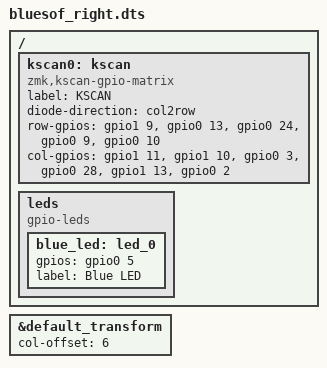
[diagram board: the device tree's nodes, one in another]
/*
 * Copyright (c) 2020 Eric Lau
 *
 * SPDX-License-Identifier: MIT
 */

#include "bluesof.dtsi"

/{
	kscan0: kscan {
		compatible = "zmk,kscan-gpio-matrix";
		label = "KSCAN";

		diode-direction = "col2row";
		row-gpios
			= <&gpio1  9 (GPIO_ACTIVE_HIGH | GPIO_PULL_DOWN)>
			, <&gpio0 13 (GPIO_ACTIVE_HIGH | GPIO_PULL_DOWN)>
			, <&gpio0 24 (GPIO_ACTIVE_HIGH | GPIO_PULL_DOWN)>
			, <&gpio0  9 (GPIO_ACTIVE_HIGH | GPIO_PULL_DOWN)>
			, <&gpio0 10 (GPIO_ACTIVE_HIGH | GPIO_PULL_DOWN)>
			;

		col-gpios
			= <&gpio1 11 GPIO_ACTIVE_HIGH>
			, <&gpio1 10 GPIO_ACTIVE_HIGH>
			, <&gpio0  3 GPIO_ACTIVE_HIGH>
			, <&gpio0 28 GPIO_ACTIVE_HIGH>
			, <&gpio1 13 GPIO_ACTIVE_HIGH>
			, <&gpio0  2 GPIO_ACTIVE_HIGH>
			;
	};

	leds {
		compatible = "gpio-leds";
		blue_led: led_0 {
			gpios = <&gpio0 5 GPIO_ACTIVE_HIGH>;
			label = "Blue LED";
		};
		};
	// vbatt {
	// 	compatible = "zmk,battery-voltage-divider";
	// 	label = "BATTERY";
	// 	io-channels = <&adc 2>;
	// 	output-ohms = <2000000>;
	// 	full-ohms = <(2000000 + 820000)>;
	// };

};

&default_transform {
		col-offset = <6>;
	};

// &i2c0 {
// 		status = "ok";
// 		compatible = "nordic,nrf-twim";
// 		sda-pin = <16>;
// 		scl-pin = <13>;
// 		clock-frequency = <100000>; 
// 	};

// &spi0 {
// 	status = "okay";
// 	cs-gpios = <&gpio1 2 GPIO_ACTIVE_LOW>;

// 	epd: il0323@0 {
// 		compatible = "gooddisplay,il0323";
// 		reg =  <0>;
// 		label = "DISPLAY";
// 		width = <80>;
// 		height = <128>;
// 		spi-max-frequency = <250000>;
// 		dc-gpios = <&gpio1 0 GPIO_ACTIVE_HIGH>;
// 		busy-gpios = <&gpio0 24 GPIO_ACTIVE_LOW>;
// 		reset-gpios = <&gpio0 22 GPIO_ACTIVE_HIGH>;
// 		pwr = [03 00 26 26];
// 		softstart = [17 17 17 17];
// 		cdi = <0xd2>;
// 		tcon = <0x22>;
// 	};
// };

/*
&i2c_max17055: max17055@49 {
	compatible = "maxim,max17055";
	label = "max17055";
	reg = <0x49>;
	design-voltage = <3860>;
	desired-voltage = <4400>;
	desired-charging-current = <2000>;
	rsense-mohms = <10>;
};
*/

